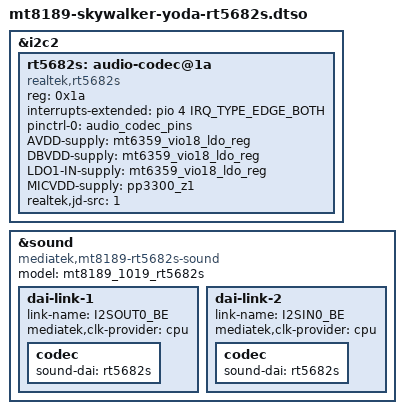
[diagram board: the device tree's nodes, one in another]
// SPDX-License-Identifier: (GPL-2.0 OR MIT)
/*
 * Copyright (C) 2025 Google Inc.
 */
/dts-v1/;
/plugin/;

#include <dt-bindings/interrupt-controller/irq.h>

&i2c2 {
	#address-cells = <1>;
	#size-cells = <0>;

	rt5682s: audio-codec@1a {
		compatible = "realtek,rt5682s";
		reg = <0x1a>;
		interrupts-extended = <&pio 4 IRQ_TYPE_EDGE_BOTH>;
		pinctrl-names = "default";
		pinctrl-0 = <&audio_codec_pins>;
		#sound-dai-cells = <0>;

		AVDD-supply = <&mt6359_vio18_ldo_reg>;
		DBVDD-supply = <&mt6359_vio18_ldo_reg>;
		LDO1-IN-supply = <&mt6359_vio18_ldo_reg>;
		MICVDD-supply = <&pp3300_z1>;
		realtek,jd-src = <1>;
		status = "okay";
	};
};

&sound {
	compatible = "mediatek,mt8189-rt5682s-sound";
	model = "mt8189_1019_rt5682s";
	status = "okay";

	dai-link-1 {
		link-name = "I2SOUT0_BE";
		mediatek,clk-provider = "cpu";

		codec {
			sound-dai = <&rt5682s>;
		};
	};

	dai-link-2 {
		link-name = "I2SIN0_BE";
		mediatek,clk-provider = "cpu";

		codec {
			sound-dai = <&rt5682s>;
		};
	};
};
